# LRFDMDM32 register map
Vendor: Texas Instruments
Registers are 32-bit, access per field, reset 0x0 unless marked. A register's access mark holds for its fields unless they carry their own. Offsets are as the file gives them; [hi:lo] are bit positions; {n}, {i} and the like mark numbered series; 'fields as' and 'values as' point back to an identical list.

## LRFDMDM32 (part 2 of 2)
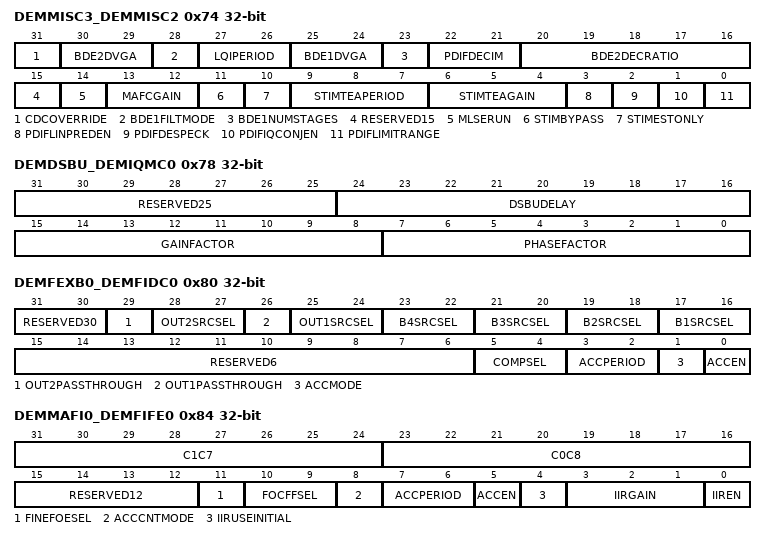
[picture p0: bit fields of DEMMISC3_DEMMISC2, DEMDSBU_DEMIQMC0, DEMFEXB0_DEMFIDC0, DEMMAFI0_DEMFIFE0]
0x74 DEMMISC3_DEMMISC2 — Internal. Only to be used through TI provided API.
  [31] CDCOVERRIDE rw — Internal. Only to be used through TI provided API.
  [30:29] BDE2DVGA rw — Internal. Only to be used through TI provided API.
    3=GAIN8 (Internal. Only to be used through TI provided API.); 2=GAIN4 (Internal. Only to be used through TI provided API.); 1=GAIN2 (Internal. Only to be used through TI provided API.); 0=GAIN1 (Internal. Only to be used through TI provided API.)
  [28] BDE1FILTMODE rw — Internal. Only to be used through TI provided API.
    1=DIV2 (Internal. Only to be used through TI provided API.); 0=DIV1 (Internal. Only to be used through TI provided API.)
  [27:26] LQIPERIOD rw — Internal. Only to be used through TI provided API.
    3=SYM1024 (Internal. Only to be used through TI provided API.); 2=SYM256 (Internal. Only to be used through TI provided API.); 1=SYM64 (Internal. Only to be used through TI provided API.); 0=SYM16 (Internal. Only to be used through TI provided API.)
  [25:24] BDE1DVGA rw — Internal. Only to be used through TI provided API.
    values as BDE2DVGA
  [23] BDE1NUMSTAGES rw — Internal. Only to be used through TI provided API.
    values as BDE1FILTMODE
  [22:21] PDIFDECIM rw — Internal. Only to be used through TI provided API.
    2=DIV4 (Internal. Only to be used through TI provided API.); 1=DIV2 (Internal. Only to be used through TI provided API.); 0=DIV1 (Internal. Only to be used through TI provided API.)
  [20:16] BDE2DECRATIO rw — Internal. Only to be used through TI provided API.
    3=DIV8 (Internal. Only to be used through TI provided API.); 2=DIV4 (Internal. Only to be used through TI provided API.); 1=DIV2 (Internal. Only to be used through TI provided API.); 0=DIV1 (Internal. Only to be used through TI provided API.)
  [15] RESERVED15 ro — Internal. Only to be used through TI provided API.
  [14] MLSERUN rw — Internal. Only to be used through TI provided API.
    1=EN (Internal. Only to be used through TI provided API.); 0=DIS (Internal. Only to be used through TI provided API.)
  [13:12] MAFCGAIN rw — Internal. Only to be used through TI provided API.
    3=ALLONES (Internal. Only to be used through TI provided API.); 0=ALLZEROS (Internal. Only to be used through TI provided API.)
  [11] STIMBYPASS rw — Internal. Only to be used through TI provided API.
    values as MLSERUN
  [10] STIMESTONLY rw — Internal. Only to be used through TI provided API.
    values as MLSERUN
  [9:7] STIMTEAPERIOD rw — Internal. Only to be used through TI provided API.
    5=SYM128 (Internal. Only to be used through TI provided API.); 4=SYM64 (Internal. Only to be used through TI provided API.); 3=SYM32 (Internal. Only to be used through TI provided API.); 2=SYM16 (Internal. Only to be used through TI provided API.); 1=SYM8 (Internal. Only to be used through TI provided API.); 0=SYM4 (Internal. Only to be used through TI provided API.)
  [6:4] STIMTEAGAIN rw — Internal. Only to be used through TI provided API.
    7=DIV4 (Internal. Only to be used through TI provided API.); 6=DIV8 (Internal. Only to be used through TI provided API.); 5=DIV16 (Internal. Only to be used through TI provided API.); 4=DIV32 (Internal. Only to be used through TI provided API.); 3=DIV64 (Internal. Only to be used through TI provided API.); 2=DIV128 (Internal. Only to be used through TI provided API.); 1=DIV256 (Internal. Only to be used through TI provided API.); 0=DIV512 (Internal. Only to be used through TI provided API.)
  [3] PDIFLINPREDEN rw — Internal. Only to be used through TI provided API.
    1=ON (Internal. Only to be used through TI provided API.); 0=OFF (Internal. Only to be used through TI provided API.)
  [2] PDIFDESPECK rw — Internal. Only to be used through TI provided API.
    values as MLSERUN
  [1] PDIFIQCONJEN rw — Internal. Only to be used through TI provided API.
    values as PDIFLINPREDEN
  [0] PDIFLIMITRANGE rw — Internal. Only to be used through TI provided API.
    values as MLSERUN
0x78 DEMDSBU_DEMIQMC0 — Internal. Only to be used through TI provided API.
  [31:25] RESERVED25 ro — Internal. Only to be used through TI provided API.
  [24:16] DSBUDELAY rw — Internal. Only to be used through TI provided API.
    255=ALLONES (Internal. Only to be used through TI provided API.); 0=ALLZEROS (Internal. Only to be used through TI provided API.)
  [15:8] GAINFACTOR rw — Internal. Only to be used through TI provided API.
    values as DSBUDELAY
  [7:0] PHASEFACTOR rw — Internal. Only to be used through TI provided API.
    values as DSBUDELAY
0x80 DEMFEXB0_DEMFIDC0 — Internal. Only to be used through TI provided API.
  [31:30] RESERVED30 ro — Internal. Only to be used through TI provided API.
  [29] OUT2PASSTHROUGH rw — Internal. Only to be used through TI provided API.
    1=ONE (Internal. Only to be used through TI provided API.); 0=ZERO (Internal. Only to be used through TI provided API.)
  [28:27] OUT2SRCSEL rw — Internal. Only to be used through TI provided API.
    2=BDE1 (Internal. Only to be used through TI provided API.); 1=CMIX (Internal. Only to be used through TI provided API.); 0=CODC (Internal. Only to be used through TI provided API.)
  [26] OUT1PASSTHROUGH rw — Internal. Only to be used through TI provided API.
    values as OUT2PASSTHROUGH
  [25:24] OUT1SRCSEL rw — Internal. Only to be used through TI provided API.
    values as OUT2SRCSEL
  [23:22] B4SRCSEL rw — Internal. Only to be used through TI provided API.
    3=ONES (Internal. Only to be used through TI provided API.); 0=ZEROS (Internal. Only to be used through TI provided API.)
  [21:20] B3SRCSEL rw — Internal. Only to be used through TI provided API.
    2=CMIX (Internal. Only to be used through TI provided API.); 1=CODC (Internal. Only to be used through TI provided API.); 0=INPUT (Internal. Only to be used through TI provided API.)
  [19:18] B2SRCSEL rw — Internal. Only to be used through TI provided API.
    2=BDE1 (Internal. Only to be used through TI provided API.); 1=CODC (Internal. Only to be used through TI provided API.); 0=INPUT (Internal. Only to be used through TI provided API.)
  [17:16] B1SRCSEL rw — Internal. Only to be used through TI provided API.
    2=BDE1 (Internal. Only to be used through TI provided API.); 1=CMIX (Internal. Only to be used through TI provided API.); 0=INPUT (Internal. Only to be used through TI provided API.)
  [15:6] RESERVED6 ro — Internal. Only to be used through TI provided API.
  [5:4] COMPSEL rw — Internal. Only to be used through TI provided API.
    2=ACC (Internal. Only to be used through TI provided API.); 0=MANUAL (Internal. Only to be used through TI provided API.)
  [3:2] ACCPERIOD rw — Internal. Only to be used through TI provided API.
    3=SMPL512 (Internal. Only to be used through TI provided API.); 2=SMPL128 (Internal. Only to be used through TI provided API.); 1=SMPL32 (Internal. Only to be used through TI provided API.); 0=SMPL8 (Internal. Only to be used through TI provided API.)
  [1] ACCMODE rw — Internal. Only to be used through TI provided API.
    1=CONT (Internal. Only to be used through TI provided API.); 0=SINGLE (Internal. Only to be used through TI provided API.)
  [0] ACCEN rw — Internal. Only to be used through TI provided API.
    values as DEMMISC3_DEMMISC2.PDIFLINPREDEN
0x84 DEMMAFI0_DEMFIFE0 — Internal. Only to be used through TI provided API.
  [31:24] C1C7 rw — Internal. Only to be used through TI provided API.
    values as DEMDSBU_DEMIQMC0.DSBUDELAY
  [23:16] C0C8 rw — Internal. Only to be used through TI provided API.
    values as DEMDSBU_DEMIQMC0.DSBUDELAY
  [15:12] RESERVED12 ro — Internal. Only to be used through TI provided API.
  [11] FINEFOESEL rw — Internal. Only to be used through TI provided API.
    1=ACC (Internal. Only to be used through TI provided API.); 0=IIR (Internal. Only to be used through TI provided API.)
  [10:9] FOCFFSEL rw — Internal. Only to be used through TI provided API.
    2=MANUAL (Internal. Only to be used through TI provided API.); 1=ACC (Internal. Only to be used through TI provided API.); 0=IIR (Internal. Only to be used through TI provided API.)
  [8] ACCCNTMODE rw — Internal. Only to be used through TI provided API.
    values as DEMFEXB0_DEMFIDC0.ACCMODE
  [7:6] ACCPERIOD rw — Internal. Only to be used through TI provided API.
    3=PER512 (Internal. Only to be used through TI provided API.); 2=PER256 (Internal. Only to be used through TI provided API.); 1=PER128 (Internal. Only to be used through TI provided API.); 0=PER64 (Internal. Only to be used through TI provided API.)
  [5] ACCEN rw — Internal. Only to be used through TI provided API.
    values as DEMMISC3_DEMMISC2.PDIFLINPREDEN
  [4] IIRUSEINITIAL rw — Internal. Only to be used through TI provided API.
    values as DEMMISC3_DEMMISC2.MLSERUN
  [3:1] IIRGAIN rw — Internal. Only to be used through TI provided API.
    7=DIV1024 (Internal. Only to be used through TI provided API.); 6=DIV512 (Internal. Only to be used through TI provided API.); 5=DIV256 (Internal. Only to be used through TI provided API.); 4=DIV128 (Internal. Only to be used through TI provided API.); 3=DIV64 (Internal. Only to be used through TI provided API.); 2=DIV32 (Internal. Only to be used through TI provided API.); 1=DIV16 (Internal. Only to be used through TI provided API.); 0=OFF (Internal. Only to be used through TI provided API.)
  [0] IIREN rw — Internal. Only to be used through TI provided API.
    values as DEMMISC3_DEMMISC2.PDIFLINPREDEN
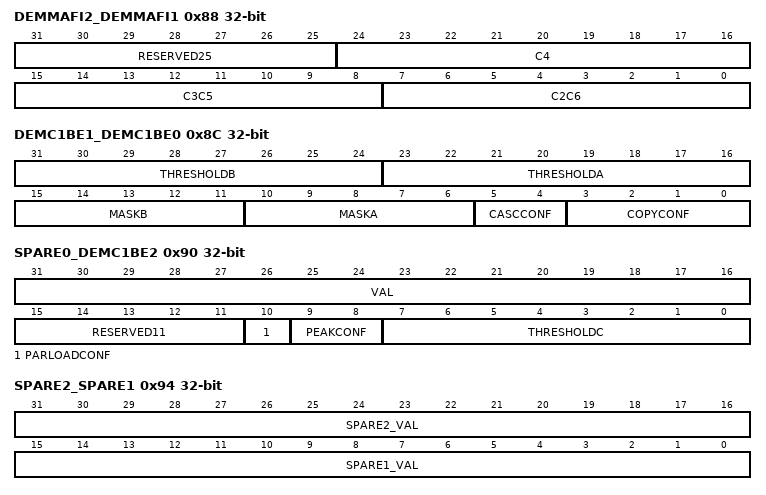
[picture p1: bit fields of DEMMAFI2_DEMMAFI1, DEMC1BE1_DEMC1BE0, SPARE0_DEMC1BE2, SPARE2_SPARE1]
0x88 DEMMAFI2_DEMMAFI1 — Internal. Only to be used through TI provided API.
  [31:25] RESERVED25 ro — Internal. Only to be used through TI provided API.
  [24:16] C4 rw — Internal. Only to be used through TI provided API.
    0x1FF=ALLONES (Internal. Only to be used through TI provided API.); 0=ALLZEROS (Internal. Only to be used through TI provided API.)
  [15:8] C3C5 rw — Internal. Only to be used through TI provided API.
    values as DEMDSBU_DEMIQMC0.DSBUDELAY
  [7:0] C2C6 rw — Internal. Only to be used through TI provided API.
    values as DEMDSBU_DEMIQMC0.DSBUDELAY
0x8C DEMC1BE1_DEMC1BE0 rw — Internal. Only to be used through TI provided API.
  [31:24] THRESHOLDB — Internal. Only to be used through TI provided API.
    values as DEMDSBU_DEMIQMC0.DSBUDELAY
  [23:16] THRESHOLDA — Internal. Only to be used through TI provided API.
    values as DEMDSBU_DEMIQMC0.DSBUDELAY
  [15:11] MASKB — Internal. Only to be used through TI provided API.
    31=ALLONES (Internal. Only to be used through TI provided API.); 0=ALLZEROS (Internal. Only to be used through TI provided API.)
  [10:6] MASKA — Internal. Only to be used through TI provided API.
    values as MASKB
  [5:4] CASCCONF — Internal. Only to be used through TI provided API.
    2=PARALLEL (Internal. Only to be used through TI provided API.); 1=SERIAL (Internal. Only to be used through TI provided API.); 0=SINGLE (Internal. Only to be used through TI provided API.)
  [3:0] COPYCONF — Internal. Only to be used through TI provided API.
    15=ALLONES (Internal. Only to be used through TI provided API.); 0=ALLZEROS (Internal. Only to be used through TI provided API.)
0x90 SPARE0_DEMC1BE2 — Internal. Only to be used through TI provided API.
  [31:16] VAL rw — Internal. Only to be used through TI provided API.
    0xFFFF=ALLONES (Internal. Only to be used through TI provided API.); 0=ALLZEROS (Internal. Only to be used through TI provided API.)
  [15:11] RESERVED11 ro — Internal. Only to be used through TI provided API.
  [10] PARLOADCONF rw — Internal. Only to be used through TI provided API.
    1=ATOD (Internal. Only to be used through TI provided API.); 0=ATOB (Internal. Only to be used through TI provided API.)
  [9:8] PEAKCONF rw — Internal. Only to be used through TI provided API.
    2=BESTAB (Internal. Only to be used through TI provided API.); 1=BEST (Internal. Only to be used through TI provided API.); 0=THRESH (Internal. Only to be used through TI provided API.)
  [7:0] THRESHOLDC rw — Internal. Only to be used through TI provided API.
    values as DEMDSBU_DEMIQMC0.DSBUDELAY
0x94 SPARE2_SPARE1 rw — Internal. Only to be used through TI provided API.
  [31:16] SPARE2_VAL — Internal. Only to be used through TI provided API.
    values as SPARE0_DEMC1BE2.VAL
  [15:0] SPARE1_VAL — Internal. Only to be used through TI provided API.
    values as SPARE0_DEMC1BE2.VAL
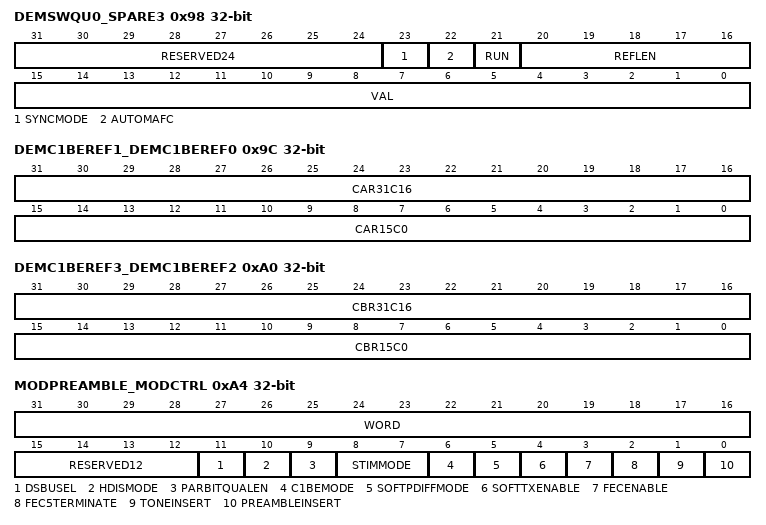
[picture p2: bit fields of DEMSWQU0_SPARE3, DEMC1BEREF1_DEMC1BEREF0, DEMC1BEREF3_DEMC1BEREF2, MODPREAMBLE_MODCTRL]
0x98 DEMSWQU0_SPARE3 — Internal. Only to be used through TI provided API.
  [31:24] RESERVED24 ro — Internal. Only to be used through TI provided API.
  [23] SYNCMODE rw — Internal. Only to be used through TI provided API.
    values as DEMFEXB0_DEMFIDC0.OUT2PASSTHROUGH
  [22] AUTOMAFC rw — Internal. Only to be used through TI provided API.
    values as DEMMISC3_DEMMISC2.PDIFLINPREDEN
  [21] RUN rw — Internal. Only to be used through TI provided API.
    values as DEMMISC3_DEMMISC2.PDIFLINPREDEN
  [20:16] REFLEN rw — Internal. Only to be used through TI provided API.
    values as DEMC1BE1_DEMC1BE0.MASKB
  [15:0] VAL rw — Internal. Only to be used through TI provided API.
    values as SPARE0_DEMC1BE2.VAL
0x9C DEMC1BEREF1_DEMC1BEREF0 rw — Internal. Only to be used through TI provided API.
  [31:16] CAR31C16 — Internal. Only to be used through TI provided API.
    values as SPARE0_DEMC1BE2.VAL
  [15:0] CAR15C0 — Internal. Only to be used through TI provided API.
    values as SPARE0_DEMC1BE2.VAL
0xA0 DEMC1BEREF3_DEMC1BEREF2 rw — Internal. Only to be used through TI provided API.
  [31:16] CBR31C16 — Internal. Only to be used through TI provided API.
    values as SPARE0_DEMC1BE2.VAL
  [15:0] CBR15C0 — Internal. Only to be used through TI provided API.
    values as SPARE0_DEMC1BE2.VAL
0xA4 MODPREAMBLE_MODCTRL — Internal. Only to be used through TI provided API.
  [31:16] WORD rw — Internal. Only to be used through TI provided API.
    values as SPARE0_DEMC1BE2.VAL
  [15:12] RESERVED12 ro — Internal. Only to be used through TI provided API.
  [11] DSBUSEL rw — Internal. Only to be used through TI provided API.
    values as DEMFEXB0_DEMFIDC0.OUT2PASSTHROUGH
  [10] HDISMODE rw — Internal. Only to be used through TI provided API.
    values as DEMMISC3_DEMMISC2.MLSERUN
  [9] PARBITQUALEN rw — Internal. Only to be used through TI provided API.
    values as DEMMISC3_DEMMISC2.PDIFLINPREDEN
  [8:7] STIMMODE rw — Internal. Only to be used through TI provided API.
    2=EARLY (Internal. Only to be used through TI provided API.); 1=LATE (Internal. Only to be used through TI provided API.); 0=NORMAL (Internal. Only to be used through TI provided API.)
  [6] C1BEMODE rw — Internal. Only to be used through TI provided API.
    1=EARLYLATE (Internal. Only to be used through TI provided API.); 0=NORMAL (Internal. Only to be used through TI provided API.)
  [5] SOFTPDIFFMODE rw — Internal. Only to be used through TI provided API.
    values as DEMMISC3_DEMMISC2.MLSERUN
  [4] SOFTTXENABLE rw — Internal. Only to be used through TI provided API.
    values as DEMMISC3_DEMMISC2.PDIFLINPREDEN
  [3] FECENABLE rw — Internal. Only to be used through TI provided API.
    values as DEMMISC3_DEMMISC2.PDIFLINPREDEN
  [2] FEC5TERMINATE rw — Internal. Only to be used through TI provided API.
    values as DEMMISC3_DEMMISC2.PDIFLINPREDEN
  [1] TONEINSERT rw — Internal. Only to be used through TI provided API.
    values as DEMMISC3_DEMMISC2.MLSERUN
  [0] PREAMBLEINSERT rw — Internal. Only to be used through TI provided API.
    values as DEMMISC3_DEMMISC2.MLSERUN
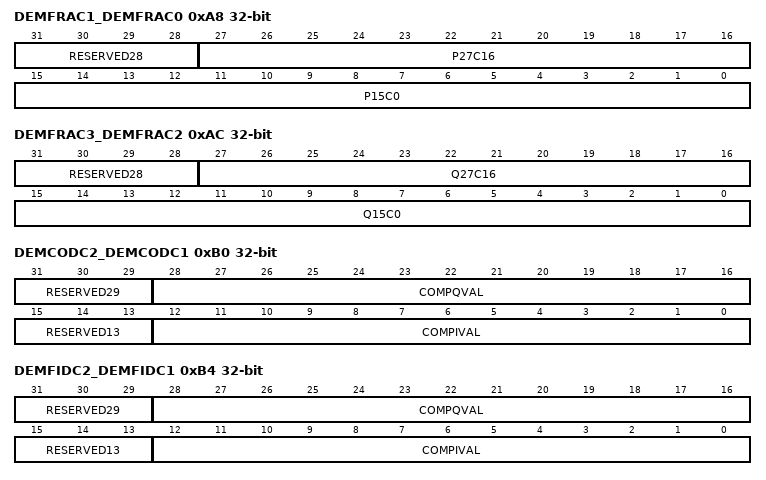
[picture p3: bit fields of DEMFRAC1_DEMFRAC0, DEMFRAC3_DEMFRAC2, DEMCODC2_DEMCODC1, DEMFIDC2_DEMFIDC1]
0xA8 DEMFRAC1_DEMFRAC0 — Internal. Only to be used through TI provided API.
  [31:28] RESERVED28 ro — Internal. Only to be used through TI provided API.
  [27:16] P27C16 rw — Internal. Only to be used through TI provided API.
    0xFFF=ALLONES (Internal. Only to be used through TI provided API.); 0=ALLZEROS (Internal. Only to be used through TI provided API.)
  [15:0] P15C0 rw — Internal. Only to be used through TI provided API.
    values as SPARE0_DEMC1BE2.VAL
0xAC DEMFRAC3_DEMFRAC2 — Internal. Only to be used through TI provided API.
  [31:28] RESERVED28 ro — Internal. Only to be used through TI provided API.
  [27:16] Q27C16 rw — Internal. Only to be used through TI provided API.
    values as DEMFRAC1_DEMFRAC0.P27C16
  [15:0] Q15C0 rw — Internal. Only to be used through TI provided API.
    values as SPARE0_DEMC1BE2.VAL
0xB0 DEMCODC2_DEMCODC1 — Internal. Only to be used through TI provided API.
  [31:29] RESERVED29 ro — Internal. Only to be used through TI provided API.
  [28:16] COMPQVAL rw — Internal. Only to be used through TI provided API.
    0x1FFF=ALLONES (Internal. Only to be used through TI provided API.); 0=ALLZEROS (Internal. Only to be used through TI provided API.)
  [15:13] RESERVED13 ro — Internal. Only to be used through TI provided API.
  [12:0] COMPIVAL rw — Internal. Only to be used through TI provided API.
    values as COMPQVAL
0xB4 DEMFIDC2_DEMFIDC1 — Internal. Only to be used through TI provided API.
  fields as DEMCODC2_DEMCODC1
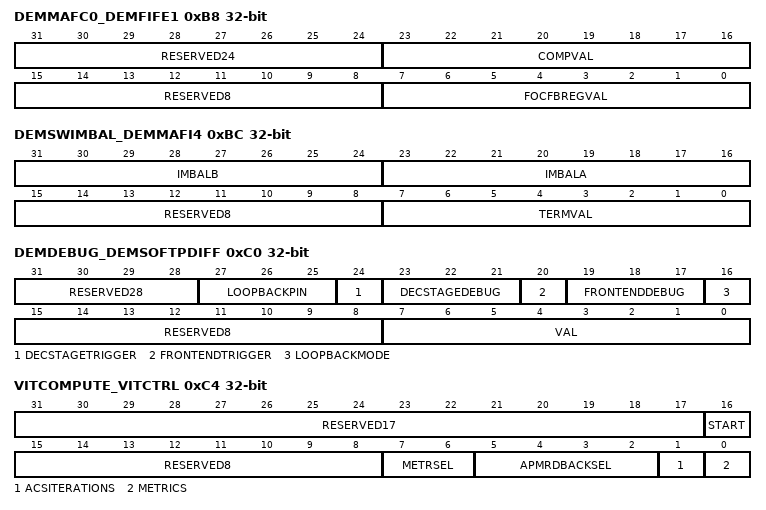
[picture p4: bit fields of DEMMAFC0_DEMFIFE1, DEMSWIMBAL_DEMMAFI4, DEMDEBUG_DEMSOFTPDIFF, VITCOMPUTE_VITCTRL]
0xB8 DEMMAFC0_DEMFIFE1 — Internal. Only to be used through TI provided API.
  [31:24] RESERVED24 ro — Internal. Only to be used through TI provided API.
  [23:16] COMPVAL rw — Internal. Only to be used through TI provided API.
    values as DEMDSBU_DEMIQMC0.DSBUDELAY
  [15:8] RESERVED8 ro — Internal. Only to be used through TI provided API.
  [7:0] FOCFBREGVAL rw — Internal. Only to be used through TI provided API.
    values as DEMDSBU_DEMIQMC0.DSBUDELAY
0xBC DEMSWIMBAL_DEMMAFI4 — Internal. Only to be used through TI provided API.
  [31:24] IMBALB rw — Internal. Only to be used through TI provided API.
    values as DEMDSBU_DEMIQMC0.DSBUDELAY
  [23:16] IMBALA rw — Internal. Only to be used through TI provided API.
    values as DEMDSBU_DEMIQMC0.DSBUDELAY
  [15:8] RESERVED8 ro — Internal. Only to be used through TI provided API.
  [7:0] TERMVAL rw — Internal. Only to be used through TI provided API.
    values as DEMDSBU_DEMIQMC0.DSBUDELAY
0xC0 DEMDEBUG_DEMSOFTPDIFF — Internal. Only to be used through TI provided API.
  [31:28] RESERVED28 ro — Internal. Only to be used through TI provided API.
  [27:25] LOOPBACKPIN rw — Internal. Only to be used through TI provided API.
    {v}=GPI{v} (Internal. Only to be used through TI provided API.) (v=0..7)
  [24] DECSTAGETRIGGER rw — Internal. Only to be used through TI provided API.
    values as DEMFEXB0_DEMFIDC0.OUT2PASSTHROUGH
  [23:21] DECSTAGEDEBUG rw — Internal. Only to be used through TI provided API.
    7=SOFD (Internal. Only to be used through TI provided API.); 6=STIM (Internal. Only to be used through TI provided API.); 5=MAFC (Internal. Only to be used through TI provided API.); 4=C1BE (Internal. Only to be used through TI provided API.); 3=MAFI (Internal. Only to be used through TI provided API.); 2=FIFE (Internal. Only to be used through TI provided API.); 1=PDIF (Internal. Only to be used through TI provided API.); 0=NOSEL (Internal. Only to be used through TI provided API.)
  [20] FRONTENDTRIGGER rw — Internal. Only to be used through TI provided API.
    values as DEMFEXB0_DEMFIDC0.OUT2PASSTHROUGH
  [19:17] FRONTENDDEBUG rw — Internal. Only to be used through TI provided API.
    7=FIDC (Internal. Only to be used through TI provided API.); 6=FRAC (Internal. Only to be used through TI provided API.); 5=CHFI (Internal. Only to be used through TI provided API.); 4=BDE2 (Internal. Only to be used through TI provided API.); 3=FEXB2 (Internal. Only to be used through TI provided API.); 2=BDE1 (Internal. Only to be used through TI provided API.); 1=IQMC (Internal. Only to be used through TI provided API.); 0=NOSEL (Internal. Only to be used through TI provided API.)
  [16] LOOPBACKMODE rw — Internal. Only to be used through TI provided API.
    values as DEMFEXB0_DEMFIDC0.OUT2PASSTHROUGH
  [15:8] RESERVED8 ro — Internal. Only to be used through TI provided API.
  [7:0] VAL rw — Internal. Only to be used through TI provided API.
    values as DEMDSBU_DEMIQMC0.DSBUDELAY
0xC4 VITCOMPUTE_VITCTRL — Internal. Only to be used through TI provided API.
  [31:17] RESERVED17 ro — Internal. Only to be used through TI provided API.
  [16] START wo — Internal. Only to be used through TI provided API.
    values as DEMFEXB0_DEMFIDC0.OUT2PASSTHROUGH
  [15:8] RESERVED8 ro — Internal. Only to be used through TI provided API.
  [7:6] METRSEL rw — Internal. Only to be used through TI provided API.
    3=MLSE (Internal. Only to be used through TI provided API.); 2=SOFD (Internal. Only to be used through TI provided API.); 1=PHAC (Internal. Only to be used through TI provided API.); 0=MET5M (Internal. Only to be used through TI provided API.)
  [5:2] APMRDBACKSEL rw — Internal. Only to be used through TI provided API.
    {v}=APM{v-8} (Internal. Only to be used through TI provided API.) (v=8..15); 0=NOSEL (Internal. Only to be used through TI provided API.)
  [1] ACSITERATIONS rw — Internal. Only to be used through TI provided API.
    1=CODE23 (Internal. Only to be used through TI provided API.); 0=CODE12 (Internal. Only to be used through TI provided API.)
  [0] METRICS rw — Internal. Only to be used through TI provided API.
    1=SOFT (Internal. Only to be used through TI provided API.); 0=HW (Internal. Only to be used through TI provided API.)
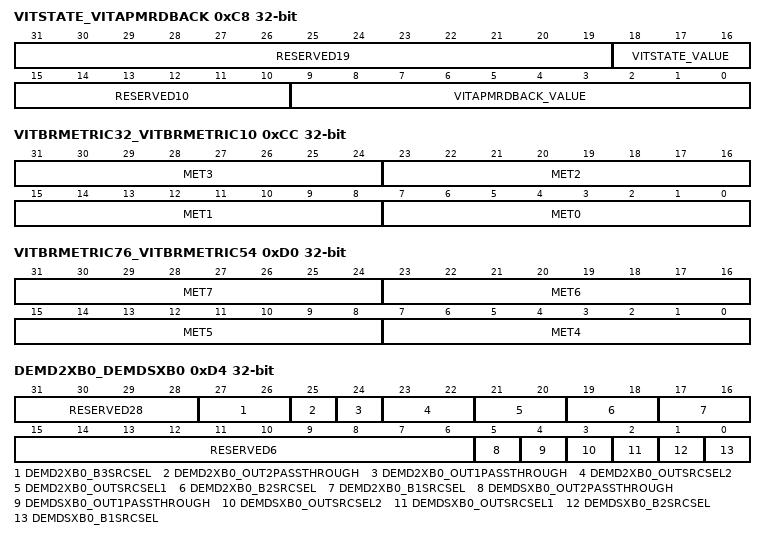
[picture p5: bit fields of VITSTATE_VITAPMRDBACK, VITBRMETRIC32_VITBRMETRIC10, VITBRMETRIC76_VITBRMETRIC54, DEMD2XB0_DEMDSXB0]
0xC8 VITSTATE_VITAPMRDBACK ro — Internal. Only to be used through TI provided API.
  [31:19] RESERVED19 — Internal. Only to be used through TI provided API.
  [18:16] VITSTATE_VALUE — Internal. Only to be used through TI provided API.
    7=ALLONES (Internal. Only to be used through TI provided API.); 0=ALLZEROS (Internal. Only to be used through TI provided API.)
  [15:10] RESERVED10 — Internal. Only to be used through TI provided API.
  [9:0] VITAPMRDBACK_VALUE — Internal. Only to be used through TI provided API.
    0x3FF=ALLONES (Internal. Only to be used through TI provided API.); 0=ALLZEROS (Internal. Only to be used through TI provided API.)
0xCC VITBRMETRIC32_VITBRMETRIC10 rw — Internal. Only to be used through TI provided API.
  [all] fields
    values as DEMDSBU_DEMIQMC0.DSBUDELAY
  [8n+7:8n] MET{n} (n=0..3) — Internal. Only to be used through TI provided API.
0xD0 VITBRMETRIC76_VITBRMETRIC54 rw — Internal. Only to be used through TI provided API.
  [all] fields
    values as DEMDSBU_DEMIQMC0.DSBUDELAY
  [8n-25:8n-32] MET{n} (n=4..7) — Internal. Only to be used through TI provided API.
0xD4 DEMD2XB0_DEMDSXB0 — Internal. Only to be used through TI provided API.
  [31:28] RESERVED28 ro — Internal. Only to be used through TI provided API.
  [27:26] DEMD2XB0_B3SRCSEL rw — Internal. Only to be used through TI provided API.
    2=STIM (Internal. Only to be used through TI provided API.); 1=MAFC (Internal. Only to be used through TI provided API.); 0=INPUT (Internal. Only to be used through TI provided API.)
  [25] DEMD2XB0_OUT2PASSTHROUGH rw — Internal. Only to be used through TI provided API.
  [24] DEMD2XB0_OUT1PASSTHROUGH rw — Internal. Only to be used through TI provided API.
  [23:22] DEMD2XB0_OUTSRCSEL2 rw — Internal. Only to be used through TI provided API.
    2=PDIF2 (Internal. Only to be used through TI provided API.); 1=STIM (Internal. Only to be used through TI provided API.); 0=MAFC (Internal. Only to be used through TI provided API.)
  [21:20] DEMD2XB0_OUTSRCSEL1 rw — Internal. Only to be used through TI provided API.
    values as DEMD2XB0_OUTSRCSEL2
  [19:18] DEMD2XB0_B2SRCSEL rw — Internal. Only to be used through TI provided API.
    2=PDIF2 (Internal. Only to be used through TI provided API.); 1=MAFC (Internal. Only to be used through TI provided API.); 0=INPUT (Internal. Only to be used through TI provided API.)
  [17:16] DEMD2XB0_B1SRCSEL rw — Internal. Only to be used through TI provided API.
    2=PDIF2 (Internal. Only to be used through TI provided API.); 1=STIM (Internal. Only to be used through TI provided API.); 0=INPUT (Internal. Only to be used through TI provided API.)
  [15:6] RESERVED6 ro — Internal. Only to be used through TI provided API.
  [5] DEMDSXB0_OUT2PASSTHROUGH rw — Internal. Only to be used through TI provided API.
    values as DEMFEXB0_DEMFIDC0.OUT2PASSTHROUGH
  [4] DEMDSXB0_OUT1PASSTHROUGH rw — Internal. Only to be used through TI provided API.
    values as DEMFEXB0_DEMFIDC0.OUT2PASSTHROUGH
  [3] DEMDSXB0_OUTSRCSEL2 rw — Internal. Only to be used through TI provided API.
    1=MAFI (Internal. Only to be used through TI provided API.); 0=FIFE (Internal. Only to be used through TI provided API.)
  [2] DEMDSXB0_OUTSRCSEL1 rw — Internal. Only to be used through TI provided API.
    values as DEMDSXB0_OUTSRCSEL2
  [1] DEMDSXB0_B2SRCSEL rw — Internal. Only to be used through TI provided API.
    1=FIFE (Internal. Only to be used through TI provided API.); 0=INPUT (Internal. Only to be used through TI provided API.)
  [0] DEMDSXB0_B1SRCSEL rw — Internal. Only to be used through TI provided API.
    1=MAFI (Internal. Only to be used through TI provided API.); 0=INPUT (Internal. Only to be used through TI provided API.)
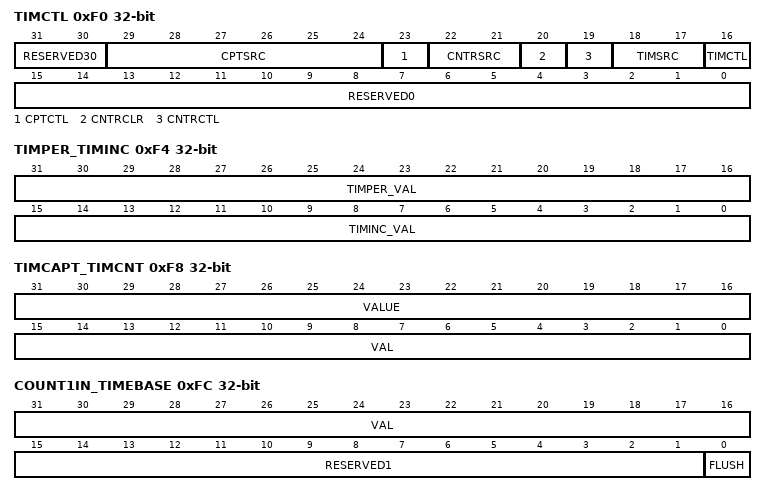
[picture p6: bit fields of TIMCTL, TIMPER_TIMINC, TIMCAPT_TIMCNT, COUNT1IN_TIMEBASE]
0xF0 TIMCTL — Internal. Only to be used through TI provided API.
  [31:30] RESERVED30 ro — Internal. Only to be used through TI provided API.
  [29:24] CPTSRC rw — Internal. Only to be used through TI provided API.
    63=ALLONES (Internal. Only to be used through TI provided API.); 0=ALLZEROS (Internal. Only to be used through TI provided API.)
  [23] CPTCTL rw — Internal. Only to be used through TI provided API.
    values as DEMMISC3_DEMMISC2.MLSERUN
  [22:21] CNTRSRC rw — Internal. Only to be used through TI provided API.
    3=CLK4BAUDF (Internal. Only to be used through TI provided API.); 2=CLK4BAUD (Internal. Only to be used through TI provided API.); 1=CLKBAUD (Internal. Only to be used through TI provided API.); 0=CLK (Internal. Only to be used through TI provided API.)
  [20] CNTRCLR rw — Internal. Only to be used through TI provided API.
    values as DEMFEXB0_DEMFIDC0.OUT2PASSTHROUGH
  [19] CNTRCTL rw — Internal. Only to be used through TI provided API.
    values as DEMFEXB0_DEMFIDC0.OUT2PASSTHROUGH
  [18:17] TIMSRC rw — Internal. Only to be used through TI provided API.
    values as CNTRSRC
  [16] TIMCTL rw — Internal. Only to be used through TI provided API.
    values as DEMMISC3_DEMMISC2.MLSERUN
  [15:0] RESERVED0 ro — Internal. Only to be used through TI provided API.
0xF4 TIMPER_TIMINC rw — Internal. Only to be used through TI provided API.
  [31:16] TIMPER_VAL — Internal. Only to be used through TI provided API.
    values as SPARE0_DEMC1BE2.VAL
  [15:0] TIMINC_VAL — Internal. Only to be used through TI provided API.
    values as SPARE0_DEMC1BE2.VAL
0xF8 TIMCAPT_TIMCNT ro — Internal. Only to be used through TI provided API.
  [31:16] VALUE — Internal. Only to be used through TI provided API.
    values as SPARE0_DEMC1BE2.VAL
  [15:0] VAL — Internal. Only to be used through TI provided API.
    values as SPARE0_DEMC1BE2.VAL
0xFC COUNT1IN_TIMEBASE — Internal. Only to be used through TI provided API.
  [31:16] VAL rw — Internal. Only to be used through TI provided API.
    values as SPARE0_DEMC1BE2.VAL
  [15:1] RESERVED1 ro — Internal. Only to be used through TI provided API.
  [0] FLUSH wo — Internal. Only to be used through TI provided API.
    values as DEMFEXB0_DEMFIDC0.OUT2PASSTHROUGH
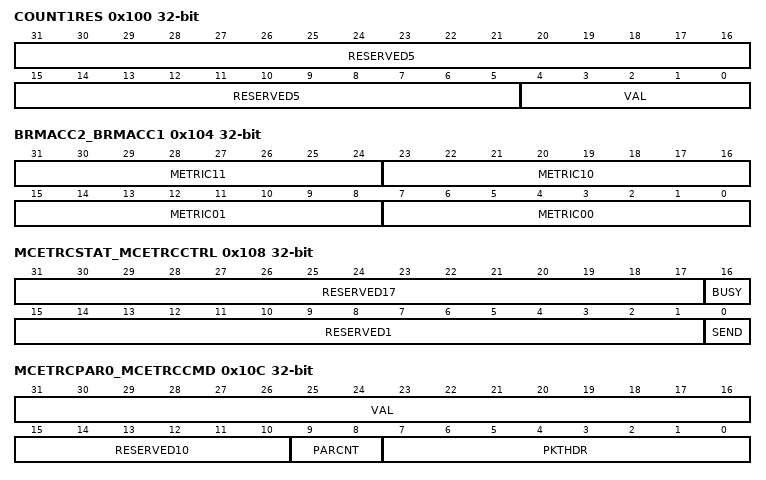
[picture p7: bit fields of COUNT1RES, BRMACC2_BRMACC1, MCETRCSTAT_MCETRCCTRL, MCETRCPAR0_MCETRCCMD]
0x100 COUNT1RES ro — Internal. Only to be used through TI provided API.
  [31:5] RESERVED5 — Internal. Only to be used through TI provided API.
  [4:0] VAL — Internal. Only to be used through TI provided API.
    values as DEMC1BE1_DEMC1BE0.MASKB
0x104 BRMACC2_BRMACC1 ro — Internal. Only to be used through TI provided API.
  [all] fields
    values as DEMDSBU_DEMIQMC0.DSBUDELAY
  [31:24] METRIC11 — Internal. Only to be used through TI provided API.
  [23:16] METRIC10 — Internal. Only to be used through TI provided API.
  [15:8] METRIC01 — Internal. Only to be used through TI provided API.
  [7:0] METRIC00 — Internal. Only to be used through TI provided API.
0x108 MCETRCSTAT_MCETRCCTRL — Internal. Only to be used through TI provided API.
  [31:17] RESERVED17 ro — Internal. Only to be used through TI provided API.
  [16] BUSY ro — Internal. Only to be used through TI provided API.
    values as DEMFEXB0_DEMFIDC0.OUT2PASSTHROUGH
  [15:1] RESERVED1 ro — Internal. Only to be used through TI provided API.
  [0] SEND wo — Internal. Only to be used through TI provided API.
    values as DEMFEXB0_DEMFIDC0.OUT2PASSTHROUGH
0x10C MCETRCPAR0_MCETRCCMD — Internal. Only to be used through TI provided API.
  [31:16] VAL rw — Internal. Only to be used through TI provided API.
    values as SPARE0_DEMC1BE2.VAL
  [15:10] RESERVED10 ro — Internal. Only to be used through TI provided API.
  [9:8] PARCNT rw — Internal. Only to be used through TI provided API.
    values as DEMMISC3_DEMMISC2.MAFCGAIN
  [7:0] PKTHDR rw — Internal. Only to be used through TI provided API.
    values as DEMDSBU_DEMIQMC0.DSBUDELAY
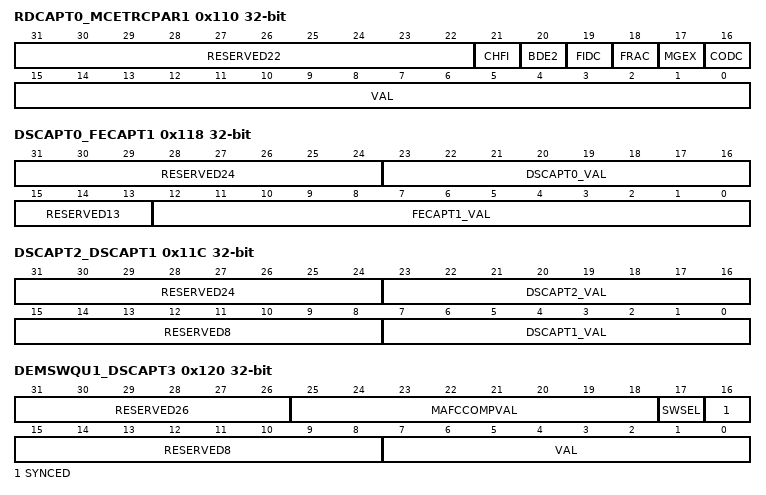
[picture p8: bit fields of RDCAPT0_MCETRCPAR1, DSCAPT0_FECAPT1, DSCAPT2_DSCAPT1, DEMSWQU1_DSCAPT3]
0x110 RDCAPT0_MCETRCPAR1 — Internal. Only to be used through TI provided API.
  [31:22] RESERVED22 ro — Internal. Only to be used through TI provided API.
  [21] CHFI wo — Internal. Only to be used through TI provided API.
    values as DEMFEXB0_DEMFIDC0.OUT2PASSTHROUGH
  [20] BDE2 wo — Internal. Only to be used through TI provided API.
    values as DEMFEXB0_DEMFIDC0.OUT2PASSTHROUGH
  [19] FIDC wo — Internal. Only to be used through TI provided API.
    values as DEMFEXB0_DEMFIDC0.OUT2PASSTHROUGH
  [18] FRAC wo — Internal. Only to be used through TI provided API.
    values as DEMFEXB0_DEMFIDC0.OUT2PASSTHROUGH
  [17] MGEX wo — Internal. Only to be used through TI provided API.
    values as DEMFEXB0_DEMFIDC0.OUT2PASSTHROUGH
  [16] CODC wo — Internal. Only to be used through TI provided API.
    values as DEMFEXB0_DEMFIDC0.OUT2PASSTHROUGH
  [15:0] VAL rw — Internal. Only to be used through TI provided API.
    values as SPARE0_DEMC1BE2.VAL
0x114 FECAPT0_RDCAPT1 — Internal. Only to be used through TI provided API.
  [31:29] RESERVED29 ro — Internal. Only to be used through TI provided API.
  [28:16] VAL rw — Internal. Only to be used through TI provided API.
    values as DEMCODC2_DEMCODC1.COMPQVAL
  [15:14] RESERVED14 ro — Internal. Only to be used through TI provided API.
  [13] COHRX wo — Internal. Only to be used through TI provided API.
    values as DEMFEXB0_DEMFIDC0.OUT2PASSTHROUGH
  [n+9] C1BEX{n} wo (n=0..3) — Internal. Only to be used through TI provided API.
    values as DEMFEXB0_DEMFIDC0.OUT2PASSTHROUGH
  [8] SOFD wo — Internal. Only to be used through TI provided API.
    values as DEMFEXB0_DEMFIDC0.OUT2PASSTHROUGH
  [7] LQIE wo — Internal. Only to be used through TI provided API.
    values as DEMFEXB0_DEMFIDC0.OUT2PASSTHROUGH
  [6] STIM wo — Internal. Only to be used through TI provided API.
    values as DEMFEXB0_DEMFIDC0.OUT2PASSTHROUGH
  [6] RESERVED6 ro — Internal. Only to be used through TI provided API.
  [5] FIFE wo — Internal. Only to be used through TI provided API.
    values as DEMFEXB0_DEMFIDC0.OUT2PASSTHROUGH
  [4] PDIF wo — Internal. Only to be used through TI provided API.
    values as DEMFEXB0_DEMFIDC0.OUT2PASSTHROUGH
  [3] CA2P wo — Internal. Only to be used through TI provided API.
    values as DEMFEXB0_DEMFIDC0.OUT2PASSTHROUGH
  [2] MAFI wo — Internal. Only to be used through TI provided API.
    values as DEMFEXB0_DEMFIDC0.OUT2PASSTHROUGH
  [1] DSBU wo — Internal. Only to be used through TI provided API.
    values as DEMFEXB0_DEMFIDC0.OUT2PASSTHROUGH
  [0] MLSEBIT wo — Internal. Only to be used through TI provided API.
    values as DEMFEXB0_DEMFIDC0.OUT2PASSTHROUGH
0x118 DSCAPT0_FECAPT1 — Internal. Only to be used through TI provided API.
  [31:24] RESERVED24 ro — Internal. Only to be used through TI provided API.
  [23:16] DSCAPT0_VAL rw — Internal. Only to be used through TI provided API.
    values as DEMDSBU_DEMIQMC0.DSBUDELAY
  [15:13] RESERVED13 ro — Internal. Only to be used through TI provided API.
  [12:0] FECAPT1_VAL rw — Internal. Only to be used through TI provided API.
    values as DEMCODC2_DEMCODC1.COMPQVAL
0x11C DSCAPT2_DSCAPT1 — Internal. Only to be used through TI provided API.
  [31:24] RESERVED24 ro — Internal. Only to be used through TI provided API.
  [23:16] DSCAPT2_VAL rw — Internal. Only to be used through TI provided API.
    values as DEMDSBU_DEMIQMC0.DSBUDELAY
  [15:8] RESERVED8 ro — Internal. Only to be used through TI provided API.
  [7:0] DSCAPT1_VAL rw — Internal. Only to be used through TI provided API.
    values as DEMDSBU_DEMIQMC0.DSBUDELAY
0x120 DEMSWQU1_DSCAPT3 — Internal. Only to be used through TI provided API.
  [31:26] RESERVED26 ro — Internal. Only to be used through TI provided API.
  [25:18] MAFCCOMPVAL ro — Internal. Only to be used through TI provided API.
    values as DEMDSBU_DEMIQMC0.DSBUDELAY
  [17] SWSEL ro — Internal. Only to be used through TI provided API.
    1=B (Internal. Only to be used through TI provided API.); 0=A (Internal. Only to be used through TI provided API.)
  [16] SYNCED ro — Internal. Only to be used through TI provided API.
    values as DEMFEXB0_DEMFIDC0.OUT2PASSTHROUGH
  [15:8] RESERVED8 ro — Internal. Only to be used through TI provided API.
  [7:0] VAL rw — Internal. Only to be used through TI provided API.
    values as DEMDSBU_DEMIQMC0.DSBUDELAY
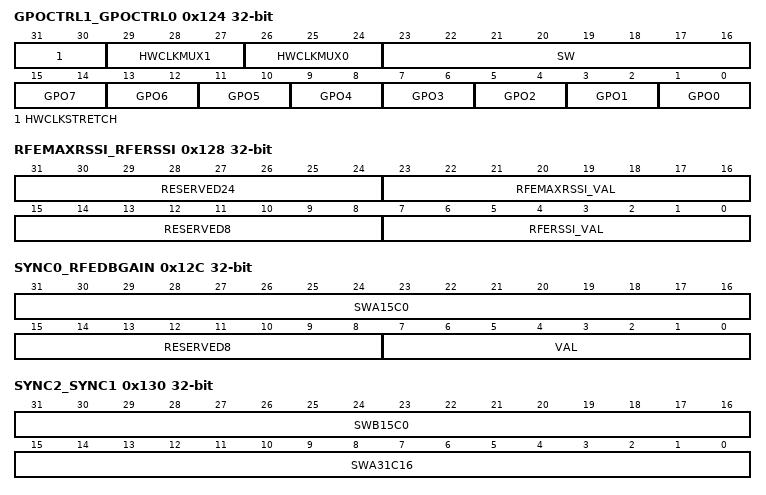
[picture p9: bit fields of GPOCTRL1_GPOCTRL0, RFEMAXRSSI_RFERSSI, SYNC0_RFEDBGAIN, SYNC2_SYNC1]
0x124 GPOCTRL1_GPOCTRL0 rw — Internal. Only to be used through TI provided API.
  [31:30] HWCLKSTRETCH — Internal. Only to be used through TI provided API.
    values as DEMFEXB0_DEMFIDC0.OUT2PASSTHROUGH
  [29:27] HWCLKMUX1 — Internal. Only to be used through TI provided API.
    values as DEMFEXB0_DEMFIDC0.OUT2PASSTHROUGH
  [26:24] HWCLKMUX0 — Internal. Only to be used through TI provided API.
    values as DEMFEXB0_DEMFIDC0.OUT2PASSTHROUGH
  [23:16] SW — Internal. Only to be used through TI provided API.
    values as DEMFEXB0_DEMFIDC0.OUT2PASSTHROUGH
  [15:14] GPO7 — Internal. Only to be used through TI provided API.
    3=THREE (Internal. Only to be used through TI provided API.); 2=TWO (Internal. Only to be used through TI provided API.); 1=TOPSM_WAIT (Internal. Only to be used through TI provided API.); 0=SW7 (Internal. Only to be used through TI provided API.)
  [13:12] GPO6 — Internal. Only to be used through TI provided API.
    3=THREE (Internal. Only to be used through TI provided API.); 2=TWO (Internal. Only to be used through TI provided API.); 1=TRANSPARENT_OUT (Internal. Only to be used through TI provided API.); 0=SW6 (Internal. Only to be used through TI provided API.)
  [11:10] GPO5 — Internal. Only to be used through TI provided API.
    3=THREE (Internal. Only to be used through TI provided API.); 2=TWO (Internal. Only to be used through TI provided API.); 1=DEM_OUT_WORD (Internal. Only to be used through TI provided API.); 0=SW5 (Internal. Only to be used through TI provided API.)
  [9:8] GPO4 — Internal. Only to be used through TI provided API.
    3=THREE (Internal. Only to be used through TI provided API.); 2=TWO (Internal. Only to be used through TI provided API.); 1=CORR_PEAK_C (Internal. Only to be used through TI provided API.); 0=SW4 (Internal. Only to be used through TI provided API.)
  [7:6] GPO3 — Internal. Only to be used through TI provided API.
    3=THREE (Internal. Only to be used through TI provided API.); 2=TWO (Internal. Only to be used through TI provided API.); 1=CORR_PEAK_B (Internal. Only to be used through TI provided API.); 0=SW3 (Internal. Only to be used through TI provided API.)
  [5:4] GPO2 — Internal. Only to be used through TI provided API.
    3=THREE (Internal. Only to be used through TI provided API.); 2=TWO (Internal. Only to be used through TI provided API.); 1=CORR_PEAK_A (Internal. Only to be used through TI provided API.); 0=SW2 (Internal. Only to be used through TI provided API.)
  [3:2] GPO1 — Internal. Only to be used through TI provided API.
    3=THREE (Internal. Only to be used through TI provided API.); 2=TWO (Internal. Only to be used through TI provided API.); 1=HWCLK1 (Internal. Only to be used through TI provided API.); 0=SW1 (Internal. Only to be used through TI provided API.)
  [1:0] GPO0 — Internal. Only to be used through TI provided API.
    3=THREE (Internal. Only to be used through TI provided API.); 2=LOOPBACK (Internal. Only to be used through TI provided API.); 1=HWCLK0 (Internal. Only to be used through TI provided API.); 0=SW0 (Internal. Only to be used through TI provided API.)
0x128 RFEMAXRSSI_RFERSSI ro — Internal. Only to be used through TI provided API.
  [31:24] RESERVED24 — Internal. Only to be used through TI provided API.
  [23:16] RFEMAXRSSI_VAL — Internal. Only to be used through TI provided API.
    values as DEMDSBU_DEMIQMC0.DSBUDELAY
  [15:8] RESERVED8 — Internal. Only to be used through TI provided API.
  [7:0] RFERSSI_VAL — Internal. Only to be used through TI provided API.
    values as DEMDSBU_DEMIQMC0.DSBUDELAY
0x12C SYNC0_RFEDBGAIN ro — Internal. Only to be used through TI provided API.
  [31:16] SWA15C0 — Internal. Only to be used through TI provided API.
    values as SPARE0_DEMC1BE2.VAL
  [15:8] RESERVED8 — Internal. Only to be used through TI provided API.
  [7:0] VAL — Internal. Only to be used through TI provided API.
    values as DEMDSBU_DEMIQMC0.DSBUDELAY
0x130 SYNC2_SYNC1 ro — Internal. Only to be used through TI provided API.
  [31:16] SWB15C0 — Internal. Only to be used through TI provided API.
    values as SPARE0_DEMC1BE2.VAL
  [15:0] SWA31C16 — Internal. Only to be used through TI provided API.
    values as SPARE0_DEMC1BE2.VAL
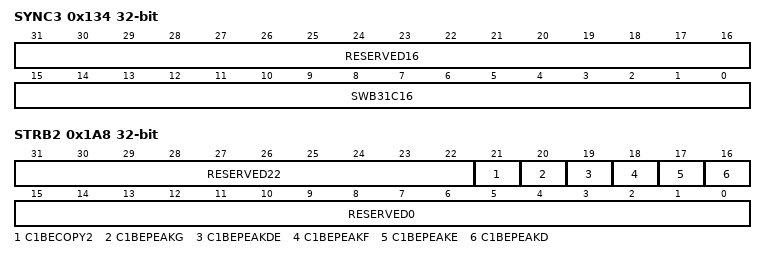
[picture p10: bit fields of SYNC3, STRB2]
0x134 SYNC3 ro — Internal. Only to be used through TI provided API.
  [31:16] RESERVED16 — Internal. Only to be used through TI provided API.
  [15:0] SWB31C16 — Internal. Only to be used through TI provided API.
    values as SPARE0_DEMC1BE2.VAL
0x1A8 STRB2 — Internal. Only to be used through TI provided API.
  [31:22] RESERVED22 ro — Internal. Only to be used through TI provided API.
  [21] C1BECOPY2 wo — Internal. Only to be used through TI provided API.
    values as DEMFEXB0_DEMFIDC0.OUT2PASSTHROUGH
  [20] C1BEPEAKG wo — Internal. Only to be used through TI provided API.
    values as DEMFEXB0_DEMFIDC0.OUT2PASSTHROUGH
  [19] C1BEPEAKDE wo — Internal. Only to be used through TI provided API.
    values as DEMFEXB0_DEMFIDC0.OUT2PASSTHROUGH
  [18] C1BEPEAKF wo — Internal. Only to be used through TI provided API.
    values as DEMFEXB0_DEMFIDC0.OUT2PASSTHROUGH
  [17] C1BEPEAKE wo — Internal. Only to be used through TI provided API.
    values as DEMFEXB0_DEMFIDC0.OUT2PASSTHROUGH
  [16] C1BEPEAKD wo — Internal. Only to be used through TI provided API.
    values as DEMFEXB0_DEMFIDC0.OUT2PASSTHROUGH
  [15:0] RESERVED0 ro — Internal. Only to be used through TI provided API.
